# S6E1B8xF register map
Vendor: Cypress; File version: 2.1
CPU: CM0PLUS r0p1, little endian, no MPU, no FPU, 2 interrupt priority bits
Registers are 8-bit, read-write, reset 0x0 unless marked. A register's access mark holds for its fields unless they carry their own. Offsets are from the block's base; [hi:lo] are bit positions.

## HDMICEC0 — HDMI-CEC ch.0
Base 0x40034000
Same registers: HDMICEC1 0x40034100
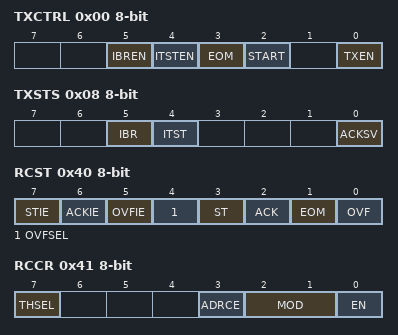
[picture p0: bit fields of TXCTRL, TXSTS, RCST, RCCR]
0x00 TXCTRL — Transmission Control Register [BHW]
  [5] IBREN — Bus error detection interrupt enable bit
  [4] ITSTEN — transmission status interrupt enable bit
  [3] EOM — EOM setting bit
  [2] START — START setting bit
  [0] TXEN — Transmission operation enable bit
0x04 TXDATA — Transmission Data Register [BHW]
  [7:0] TXDATA — Transmission Data
0x08 TXSTS — Transmission Status Register [BHW]
  [5] IBR — Bus error detection interrupt request bit
  [4] ITST — Transmission status interrupt request bit
  [0] ACKSV ro — ACK cycle value bit
0x0C SFREE — Signal Free Time Setting Register [BHW]
  [3:0] SFREE — Signal free time setting bits
0x40 RCST — Reception Interrupt Control Register [BHW]
  [7] STIE — Start bit interrupt enable bit
  [6] ACKIE — ACK interrupt enable bit
  [5] OVFIE — Counter overflow interrupt enable bit
  [4] OVFSEL — Counter overflow detection condition setting bit
  [3] ST — Start bit detection bit
  [2] ACK — ACK: ACK detection bit
  [1] EOM — EOM detection bit
  [0] OVF — Counter overflow detection bit
0x41 RCCR — Reception Control Register [BHW]
  [7] THSEL — Threshold selection bit
  [3] ADRCE — Address comparison enable bit
  [2:1] MOD — Operation mode setting bits
  [0] EN — Operation enable bit
0x44 RCDAHW — Minimum Pulse Width Setting Register [BHW]
  [7:0] RCDAHW — Set the minimum pulse width duration
0x45 RCSHW — Start Bit Detection Width Setting Register [BHW]
  [7:0] RCSHW — Set a duration of the start bit
0x49 RCDBHW — Threshold Value Setting Register [BHW]
  [7:0] RCDBHW — Set the threshold value of data reception signal width
0x4C RCADR2 — Device Address Setting Register 2 [BHW]
  [4:0] RCADR2 — Device Address 2
0x4D RCADR1 — Device Address Setting Register 1 [BHW]
  [4:0] RCADR1 — Device Address 1
0x50 RCDTHL ro — Data Save Register (High-Low) [BHW]
  [7:0] RCDTHL — Used to store received data
0x51 RCDTHH ro — Data Save Register (High-High) [BHW]
  [7:0] RCDTHH — Used to store received data
0x54 RCDTLL ro — Data Save Register (Low-Low) [BHW]
  [7:0] RCDTLL — Used to store received data
0x55 RCDTLH ro — Data Save Register (Low-High) [BHW]
  [7:0] RCDTLH — Used to store received data
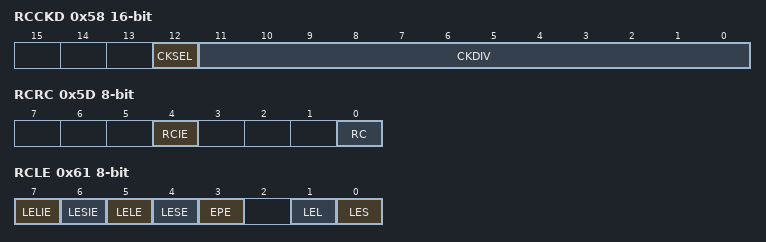
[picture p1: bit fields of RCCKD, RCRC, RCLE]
0x58 RCCKD 16-bit — Clock Division Setting Register [HW]
  [12] CKSEL — Operating clock selection bit
  [11:0] CKDIV — Operating clock division setting bits
0x5C RCRHW — Repeat Code Detection Width Setting Register [BHW]
  [7:0] RCRHW — Set the detection width for a repeart code
0x5D RCRC — Repeat Code Interrupt Control Register [BHW]
  [4] RCIE — Repeat Code Interrupt enable bit
  [0] RC — Repeat code detection flag bit
0x61 RCLE — Data Bit Width Violation Control Register [BHW]
  [7] LELIE — Maximum data bit width violation interrupt enable bit
  [6] LESIE — Minimum data bit width violation interrupt enable bit
  [5] LELE — Maximum data bit width violation detection enable bit
  [4] LESE — Minimum data bit width violation detection enable bit
  [3] EPE — Error pulse output enable bit
  [1] LEL — Maximum data bit width violation detection flag bit
  [0] LES — Minimum data bit width violation detection flag bit
0x64 RCLESW — Minimum Data Bit Width Setting Register [BHW]
  [7:0] RCLESW — Minimum data bit width setting bits
0x65 RCLELW — Maximum Data Bit Width Setting Register [BHW]
  [7:0] RCLELW — Maximum data bit width setting bits

## LVD — Low-voltage Detection
Base 0x40035000
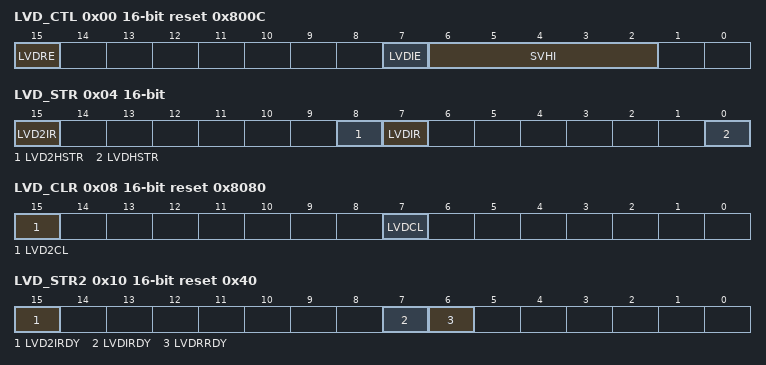
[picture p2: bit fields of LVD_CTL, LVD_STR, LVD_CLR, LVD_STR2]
0x00 LVD_CTL 16-bit reset 0x800C — Low-voltage Detection Voltage Control Register [BHW]
  [15] LVDRE — Low-voltage detection reset operation enable bit
  [7] LVDIE — Low-voltage detection interrupt enable bit
  [6:2] SVHI — Low-voltage detection interrupt voltage setting bits
0x04 LVD_STR 16-bit ro — Low-voltage Detection Interrupt Factor Register [BHW]
  [15] LVD2IR — Low-voltage detection 2 interrupt factor bit
  [8] LVD2HSTR — Voltage of VCC is higher than the setting of SVH2RLI
  [7] LVDIR — Low-voltage detection interrupt factor bit
  [0] LVDHSTR — Voltage of VCC is higher than the setting of SVHRLI
0x08 LVD_CLR 16-bit reset 0x8080 — Low-voltage Detection Interrupt Factor Clear Register [BHW]
  [15] LVD2CL — Low-voltage detection 2 interrupt factor clear bit
  [7] LVDCL — Low-voltage detection interrupt factor clear bit
0x0C LVD_RLR 32-bit reset 0x1 — Low-voltage Detection Voltage Protection Register [W]
  [31:0] LVDLCK — Low-voltage Detection Voltage Control Register protection bits
0x10 LVD_STR2 16-bit ro reset 0x40 — Low-voltage Detection Circuit Status Register [BHW]
  [15] LVD2IRDY — Low-voltage detection 2 interrupt status flag
  [7] LVDIRDY — Low-voltage detection interrupt status flag
  [6] LVDRRDY — Low-voltage detection reset status flag
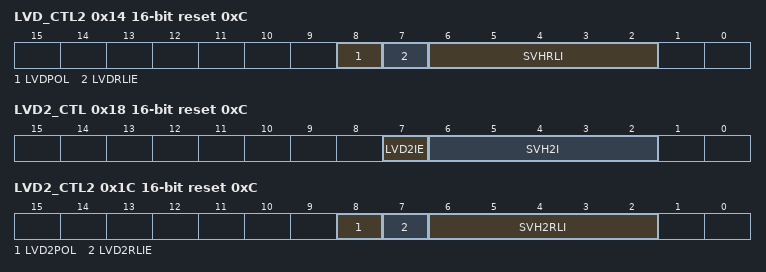
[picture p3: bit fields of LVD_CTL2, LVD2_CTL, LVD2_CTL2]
0x14 LVD_CTL2 16-bit reset 0xC — Low-voltage Detection Release Voltage Control Register [BHW]
  [8] LVDPOL — Low-voltage detection polarity setting bit
  [7] LVDRLIE — Low-voltage detection release voltage setting enable bit
  [6:2] SVHRLI — Low-voltage detection release voltage setting bits
0x18 LVD2_CTL 16-bit reset 0xC — Low-Voltage Detection Channel 2 Voltage Control Register [BHW]
  [7] LVD2IE — Low-voltage detection 2 interrupt enable bit
  [6:2] SVH2I — Low-voltage detection 2 interrupt voltage setting bits
0x1C LVD2_CTL2 16-bit reset 0xC — Low-Voltage Detection Channel 2 Release Voltage Control Register [BHW]
  [8] LVD2POL — Low-voltage detection 2 polarity setting bits
  [7] LVD2RLIE — Low-voltage detection 2 release voltage setting enable bit
  [6:2] SVH2RLI — Low-voltage detection 2 release voltage setting bits
